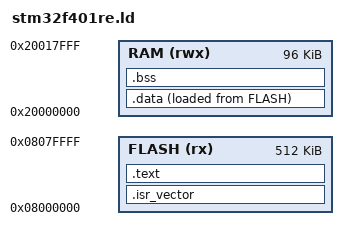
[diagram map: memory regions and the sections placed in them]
/* STM32F401RE: 512 KB of flash at 0x08000000, 96 KB of SRAM at 0x20000000. */

MEMORY
{
    FLASH (rx)  : ORIGIN = 0x08000000, LENGTH = 512K
    RAM   (rwx) : ORIGIN = 0x20000000, LENGTH = 96K
}

_estack = ORIGIN(RAM) + LENGTH(RAM);

ENTRY(Reset_Handler)

SECTIONS
{
    .isr_vector : { KEEP(*(.isr_vector)) } > FLASH

    .text : { *(.text*) *(.rodata*) } > FLASH

    _sidata = LOADADDR(.data);

    .data :
    {
        _sdata = .;
        *(.data*)
        _edata = .;
    } > RAM AT > FLASH

    .bss (NOLOAD) :
    {
        _sbss = .;
        *(.bss*) *(COMMON)
        _ebss = .;
    } > RAM

    /DISCARD/ : { *(.ARM.exidx*) *(.comment) }
}
